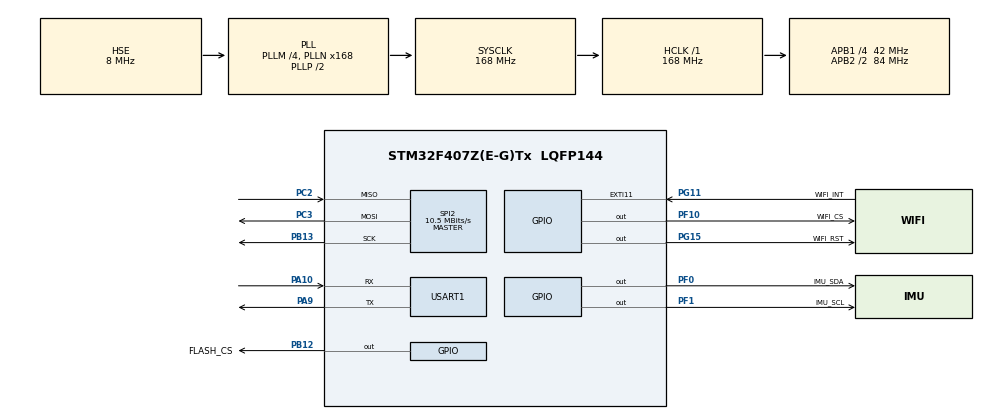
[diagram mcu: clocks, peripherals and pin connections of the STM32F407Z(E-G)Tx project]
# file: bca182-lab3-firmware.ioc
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FREERTOS.Tasks01=SensorTask,24,512,sensor_task,Default,NULL,Dynamic,NULL,NULL;NetworkTask,24,1536,network_task,Default,NULL,Dynamic,NULL,NULL
FREERTOS.configCHECK_FOR_STACK_OVERFLOW=2
FREERTOS.configTOTAL_HEAP_SIZE=49152
FREERTOS.configUSE_MALLOC_FAILED_HOOK=1
FREERTOS.configUSE_PREEMPTION=1
Mcu.Family=STM32F4
Mcu.Name=STM32F407Z(E-G)Tx
Mcu.Package=LQFP144
NVIC.EXTI15_10_IRQn=true\:5\:0\:false\:false\:true\:true\:true\:true\:true
NVIC.PriorityGroup=NVIC_PRIORITYGROUP_4
NVIC.SPI2_IRQn=true\:5\:0\:false\:false\:true\:true\:true\:true\:true
NVIC.TIM6_DAC_IRQn=true\:15\:0\:false\:false\:true\:false\:false\:true\:true
NVIC.TimeBase=TIM6_DAC_IRQn
NVIC.TimeBaseIP=TIM6
PA10.Mode=Asynchronous
PA10.Signal=USART1_RX
PA13.Mode=Serial_Wire
PA13.Signal=SYS_JTMS-SWDIO
PA14.Mode=Serial_Wire
PA14.Signal=SYS_JTCK-SWCLK
PA9.Mode=Asynchronous
PA9.Signal=USART1_TX
PB12.GPIO_Label=FLASH_CS
PB12.PinState=GPIO_PIN_SET
PB12.Signal=GPIO_Output
PB13.Mode=Full_Duplex_Master
PB13.Signal=SPI2_SCK
PC14-OSC32_IN.Mode=LSE-External-Oscillator
PC14-OSC32_IN.Signal=RCC_OSC32_IN
PC15-OSC32_OUT.Mode=LSE-External-Oscillator
PC15-OSC32_OUT.Signal=RCC_OSC32_OUT
PC2.Mode=Full_Duplex_Master
PC2.Signal=SPI2_MISO
PC3.Mode=Full_Duplex_Master
PC3.Signal=SPI2_MOSI
PF0.GPIO_Label=IMU_SDA
PF0.GPIO_ModeDefaultOutputPP=GPIO_MODE_OUTPUT_OD
PF0.GPIO_PuPd=GPIO_PULLUP
PF0.PinState=GPIO_PIN_SET
PF0.Signal=GPIO_Output
PF1.GPIO_Label=IMU_SCL
PF1.GPIO_ModeDefaultOutputPP=GPIO_MODE_OUTPUT_OD
PF1.GPIO_PuPd=GPIO_PULLUP
PF1.PinState=GPIO_PIN_SET
PF1.Signal=GPIO_Output
PF10.GPIO_Label=WIFI_CS
PF10.GPIO_Speed=GPIO_SPEED_FREQ_VERY_HIGH
PF10.PinState=GPIO_PIN_SET
PF10.Signal=GPIO_Output
PG11.GPIO_Label=WIFI_INT
PG11.GPIO_ModeDefaultEXTI=GPIO_MODE_IT_FALLING
PG11.GPIO_PuPd=GPIO_PULLUP
PG11.Signal=GPXTI11
PG15.GPIO_Label=WIFI_RST
PG15.PinState=GPIO_PIN_RESET
PG15.Signal=GPIO_Output
PH0-OSC_IN.Mode=HSE-External-Oscillator
PH0-OSC_IN.Signal=RCC_OSC_IN
PH1-OSC_OUT.Mode=HSE-External-Oscillator
PH1-OSC_OUT.Signal=RCC_OSC_OUT
ProjectManager.HeapSize=0x200
ProjectManager.StackSize=0x400
ProjectManager.TargetToolchain=Makefile
RCC.48MHZClocksFreq_Value=84000000
RCC.AHBFreq_Value=168000000
RCC.APB1CLKDivider=RCC_HCLK_DIV4
RCC.APB1Freq_Value=42000000
RCC.APB1TimFreq_Value=84000000
RCC.APB2CLKDivider=RCC_HCLK_DIV2
RCC.APB2Freq_Value=84000000
RCC.APB2TimFreq_Value=168000000
RCC.CortexFreq_Value=168000000
RCC.HCLKFreq_Value=168000000
RCC.HSE_VALUE=8000000
RCC.HSI_VALUE=16000000
RCC.PLLM=4
RCC.PLLN=168
RCC.PLLSourceVirtual=RCC_PLLSOURCE_HSE
RCC.SYSCLKFreq_VALUE=168000000
RCC.SYSCLKSource=RCC_SYSCLKSOURCE_PLLCLK
RCC.VCOOutputFreq_Value=336000000
SPI2.BaudRatePrescaler=SPI_BAUDRATEPRESCALER_4
SPI2.CalculateBaudRate=10.5 MBits/s
SPI2.Direction=SPI_DIRECTION_2LINES
SPI2.Mode=SPI_MODE_MASTER
SPI2.VirtualType=VM_MASTER
USART1.VirtualMode=VM_ASYNC
VP_FREERTOS_VS_CMSIS_V2.Mode=CMSIS_V2
VP_SYS_VS_tim6.Mode=TIM6
board=custom

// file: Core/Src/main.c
/* USER CODE BEGIN Header */
/**
  ******************************************************************************
  * @file           : main.c
  * @brief          : Main program body
  ******************************************************************************
  * @attention
  *
  * Copyright (c) 2026 STMicroelectronics.
  * All rights reserved.
  *
  * This software is licensed under terms that can be found in the LICENSE file
  * in the root directory of this software component.
  * If no LICENSE file comes with this software, it is provided AS-IS.
  *
  ******************************************************************************
  */
/* USER CODE END Header */
#include "main.h"
#include "cmsis_os.h"
#include "spi.h"
#include "usart.h"
#include "gpio.h"

/* USER CODE BEGIN Includes */
#include "rw007.h"
/* USER CODE END Includes */

void SystemClock_Config(void);
void MX_FREERTOS_Init(void);

int main(void)
{

  /* MCU Configuration--------------------------------------------------------*/

  /* Reset of all peripherals, Initializes the Flash interface and the Systick. */
  HAL_Init();

  /* Configure the system clock */
  SystemClock_Config();

  /* Initialize all configured peripherals */
  MX_GPIO_Init();
  MX_SPI2_Init();
  MX_USART1_UART_Init();

  /* Init scheduler */
  osKernelInitialize();  /* Call init function for freertos objects (in cmsis_os2.c) */
  MX_FREERTOS_Init();

  /* Start scheduler */
  osKernelStart();

  /* We should never get here as control is now taken by the scheduler */

  /* Infinite loop */
  while (1)
  {

  }
}

void SystemClock_Config(void)
{
  RCC_OscInitTypeDef RCC_OscInitStruct = {0};
  RCC_ClkInitTypeDef RCC_ClkInitStruct = {0};

  /** Configure the main internal regulator output voltage
  */
  __HAL_RCC_PWR_CLK_ENABLE();
  __HAL_PWR_VOLTAGESCALING_CONFIG(PWR_REGULATOR_VOLTAGE_SCALE1);

  /** Initializes the RCC Oscillators according to the specified parameters
  * in the RCC_OscInitTypeDef structure.
  */
  RCC_OscInitStruct.OscillatorType = RCC_OSCILLATORTYPE_HSE;
  RCC_OscInitStruct.HSEState = RCC_HSE_ON;
  RCC_OscInitStruct.PLL.PLLState = RCC_PLL_ON;
  RCC_OscInitStruct.PLL.PLLSource = RCC_PLLSOURCE_HSE;
  RCC_OscInitStruct.PLL.PLLM = 4;
  RCC_OscInitStruct.PLL.PLLN = 168;
  RCC_OscInitStruct.PLL.PLLP = RCC_PLLP_DIV2;
  RCC_OscInitStruct.PLL.PLLQ = 4;
  if (HAL_RCC_OscConfig(&RCC_OscInitStruct) != HAL_OK)
  {
    Error_Handler();
  }

  /** Initializes the CPU, AHB and APB buses clocks
  */
  RCC_ClkInitStruct.ClockType = RCC_CLOCKTYPE_HCLK|RCC_CLOCKTYPE_SYSCLK
                              |RCC_CLOCKTYPE_PCLK1|RCC_CLOCKTYPE_PCLK2;
  RCC_ClkInitStruct.SYSCLKSource = RCC_SYSCLKSOURCE_PLLCLK;
  RCC_ClkInitStruct.AHBCLKDivider = RCC_SYSCLK_DIV1;
  RCC_ClkInitStruct.APB1CLKDivider = RCC_HCLK_DIV4;
  RCC_ClkInitStruct.APB2CLKDivider = RCC_HCLK_DIV2;

  if (HAL_RCC_ClockConfig(&RCC_ClkInitStruct, FLASH_LATENCY_5) != HAL_OK)
  {
    Error_Handler();
  }
}

/* USER CODE BEGIN 4 */
/* EXTI line callback: the RW007's INT/BUSY pin (PG11) signals that the module
 * is ready for the next SPI phase or has data for us. */
void HAL_GPIO_EXTI_Callback(uint16_t GPIO_Pin)
{
  if (GPIO_Pin == WIFI_INT_Pin)
    rw007_isr();
}
/* USER CODE END 4 */

void HAL_TIM_PeriodElapsedCallback(TIM_HandleTypeDef *htim)
{
  if (htim->Instance == TIM6)
  {
    HAL_IncTick();
  }
}

void Error_Handler(void)
{
  __disable_irq();
  while (1)
  {
  }
}

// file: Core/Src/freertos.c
/* USER CODE BEGIN Header */
/**
  ******************************************************************************
  * File Name          : freertos.c
  * Description        : Code for freertos applications
  ******************************************************************************
  * @attention
  *
  * Copyright (c) 2026 STMicroelectronics.
  * All rights reserved.
  *
  * This software is licensed under terms that can be found in the LICENSE file
  * in the root directory of this software component.
  * If no LICENSE file comes with this software, it is provided AS-IS.
  *
  ******************************************************************************
  */
/* USER CODE END Header */

#include "FreeRTOS.h"
#include "task.h"
#include "main.h"
#include "cmsis_os.h"

/* USER CODE BEGIN Includes */
#include "app.h"
/* USER CODE END Includes */

/* Definitions for SensorTask */
osThreadId_t SensorTaskHandle;
const osThreadAttr_t SensorTask_attributes = {
  .name = "SensorTask",
  .stack_size = 512 * 4,
  .priority = (osPriority_t) osPriorityNormal,
};
/* Definitions for NetworkTask */
osThreadId_t NetworkTaskHandle;
const osThreadAttr_t NetworkTask_attributes = {
  .name = "NetworkTask",
  .stack_size = 1536 * 4,
  .priority = (osPriority_t) osPriorityNormal,
};

void sensor_task(void *argument);
void network_task(void *argument);

void MX_FREERTOS_Init(void); /* (MISRA C 2004 rule 8.1) */

/* Hook prototypes */
void vApplicationStackOverflowHook(xTaskHandle xTask, signed char *pcTaskName);
void vApplicationMallocFailedHook(void);

/* USER CODE BEGIN 4 */
void vApplicationStackOverflowHook(xTaskHandle xTask, signed char *pcTaskName)
{
  (void)xTask;
  app_stack_overflow((const char *)pcTaskName);
  taskDISABLE_INTERRUPTS();
  for (;;) {
  }
}
/* USER CODE END 4 */

/* USER CODE BEGIN 5 */
void vApplicationMallocFailedHook(void)
{
  app_malloc_failed();
}
/* USER CODE END 5 */

void MX_FREERTOS_Init(void) {
  /* USER CODE BEGIN Init */
  app_init();
  /* USER CODE END Init */

  /* Create the thread(s) */
  /* creation of SensorTask */
  SensorTaskHandle = osThreadNew(sensor_task, NULL, &SensorTask_attributes);

  /* creation of NetworkTask */
  NetworkTaskHandle = osThreadNew(network_task, NULL, &NetworkTask_attributes);

}

void sensor_task(void *argument)
{
  /* USER CODE BEGIN sensor_task */
  (void)argument;
  app_sensor_task();   /* never returns */
  /* USER CODE END sensor_task */
}

void network_task(void *argument)
{
  /* USER CODE BEGIN network_task */
  (void)argument;
  app_network_task();  /* never returns */
  /* USER CODE END network_task */
}
